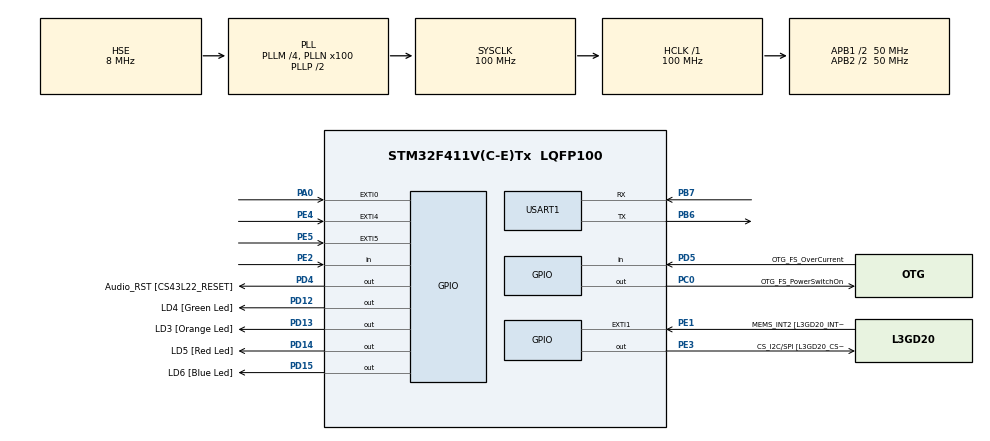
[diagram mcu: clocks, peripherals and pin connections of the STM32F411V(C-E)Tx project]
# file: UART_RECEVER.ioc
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Mcu.Family=STM32F4
Mcu.Name=STM32F411V(C-E)Tx
Mcu.Package=LQFP100
NVIC.PriorityGroup=NVIC_PRIORITYGROUP_0
NVIC.TIM1_UP_TIM10_IRQn=true\:0\:0\:false\:false\:true\:true
NVIC.USART1_IRQn=true\:0\:0\:false\:false\:true\:true
PA0-WKUP.GPIO_ModeDefaultEXTI=GPIO_MODE_EVT_RISING
PA0-WKUP.Signal=GPXTI0
PB6.Mode=Asynchronous
PB6.Signal=USART1_TX
PB7.Mode=Asynchronous
PB7.Signal=USART1_RX
PC0.GPIO_Label=OTG_FS_PowerSwitchOn
PC0.PinState=GPIO_PIN_SET
PC0.Signal=GPIO_Output
PD12.GPIO_Label=LD4 [Green Led]
PD12.GPIO_PuPd=GPIO_NOPULL
PD12.GPIO_Speed=GPIO_SPEED_FREQ_LOW
PD12.Signal=GPIO_Output
PD13.GPIO_Label=LD3 [Orange Led]
PD13.GPIO_PuPd=GPIO_NOPULL
PD13.GPIO_Speed=GPIO_SPEED_FREQ_LOW
PD13.Signal=GPIO_Output
PD14.GPIO_Label=LD5 [Red Led]
PD14.GPIO_PuPd=GPIO_NOPULL
PD14.GPIO_Speed=GPIO_SPEED_FREQ_LOW
PD14.Signal=GPIO_Output
PD15.GPIO_Label=LD6 [Blue Led]
PD15.GPIO_PuPd=GPIO_NOPULL
PD15.GPIO_Speed=GPIO_SPEED_FREQ_LOW
PD15.Signal=GPIO_Output
PD4.GPIO_Label=Audio_RST [CS43L22_RESET]
PD4.Signal=GPIO_Output
PD5.GPIO_Label=OTG_FS_OverCurrent
PD5.Signal=GPIO_Input
PE1.GPIO_Label=MEMS_INT2 [L3GD20_INT2]
PE1.GPIO_ModeDefaultEXTI=GPIO_MODE_EVT_RISING
PE1.Signal=GPXTI1
PE2.Signal=GPIO_Input
PE3.GPIO_Label=CS_I2C/SPI [L3GD20_CS_I2C/SPI]
PE3.Signal=GPIO_Output
PE4.GPIO_ModeDefaultEXTI=GPIO_MODE_EVT_RISING
PE4.Signal=GPXTI4
PE5.GPIO_ModeDefaultEXTI=GPIO_MODE_EVT_RISING
PE5.Signal=GPXTI5
PH0\ -\ OSC_IN.Mode=HSE-External-Oscillator
PH0\ -\ OSC_IN.Signal=RCC_OSC_IN
PH1\ -\ OSC_OUT.Mode=HSE-External-Oscillator
PH1\ -\ OSC_OUT.Signal=RCC_OSC_OUT
ProjectManager.HeapSize=0x200
ProjectManager.StackSize=0x400
ProjectManager.TargetToolchain=SW4STM32
RCC.48MHZClocksFreq_Value=25000000
RCC.AHBFreq_Value=100000000
RCC.APB1CLKDivider=RCC_HCLK_DIV2
RCC.APB1Freq_Value=50000000
RCC.APB1TimFreq_Value=100000000
RCC.APB2CLKDivider=RCC_HCLK_DIV2
RCC.APB2Freq_Value=50000000
RCC.APB2TimFreq_Value=100000000
RCC.CortexFreq_Value=100000000
RCC.HCLKFreq_Value=100000000
RCC.HSE_VALUE=8000000
RCC.HSI_VALUE=16000000
RCC.LSE_VALUE=32768
RCC.PLLI2SM=5
RCC.PLLI2SN=200
RCC.PLLM=4
RCC.PLLN=100
RCC.PLLQ=8
RCC.PLLSourceVirtual=RCC_PLLSOURCE_HSE
RCC.SYSCLKFreq_VALUE=100000000
RCC.SYSCLKSource=RCC_SYSCLKSOURCE_PLLCLK
RCC.VCOOutputFreq_Value=200000000
TIM10.Period=9999
TIM10.Prescaler=9999
USART1.VirtualMode=VM_ASYNC
VP_TIM10_VS_ClockSourceINT.Mode=Enable_Timer
board=32F411EDISCOVERY

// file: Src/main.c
/**
  ******************************************************************************
  * @file           : main.c
  * @brief          : Main program body
  ******************************************************************************
  ** This notice applies to any and all portions of this file
  * that are not between comment pairs USER CODE BEGIN and
  * USER CODE END. Other portions of this file, whether
  * inserted by the user or by software development tools
  * are owned by their respective copyright owners.
  *
  * COPYRIGHT(c) 2018 STMicroelectronics
  *
  * Redistribution and use in source and binary forms, with or without modification,
  * are permitted provided that the following conditions are met:
  *   1. Redistributions of source code must retain the above copyright notice,
  *      this list of conditions and the following disclaimer.
  *   2. Redistributions in binary form must reproduce the above copyright notice,
  *      this list of conditions and the following disclaimer in the documentation
  *      and/or other materials provided with the distribution.
  *   3. Neither the name of STMicroelectronics nor the names of its contributors
  *      may be used to endorse or promote products derived from this software
  *      without specific prior written permission.
  *
  * THIS SOFTWARE IS PROVIDED BY THE COPYRIGHT HOLDERS AND CONTRIBUTORS "AS IS"
  * AND ANY EXPRESS OR IMPLIED WARRANTIES, INCLUDING, BUT NOT LIMITED TO, THE
  * IMPLIED WARRANTIES OF MERCHANTABILITY AND FITNESS FOR A PARTICULAR PURPOSE ARE
  * DISCLAIMED. IN NO EVENT SHALL THE COPYRIGHT HOLDER OR CONTRIBUTORS BE LIABLE
  * FOR ANY DIRECT, INDIRECT, INCIDENTAL, SPECIAL, EXEMPLARY, OR CONSEQUENTIAL
  * DAMAGES (INCLUDING, BUT NOT LIMITED TO, PROCUREMENT OF SUBSTITUTE GOODS OR
  * SERVICES; LOSS OF USE, DATA, OR PROFITS; OR BUSINESS INTERRUPTION) HOWEVER
  * CAUSED AND ON ANY THEORY OF LIABILITY, WHETHER IN CONTRACT, STRICT LIABILITY,
  * OR TORT (INCLUDING NEGLIGENCE OR OTHERWISE) ARISING IN ANY WAY OUT OF THE USE
  * OF THIS SOFTWARE, EVEN IF ADVISED OF THE POSSIBILITY OF SUCH DAMAGE.
  *
  ******************************************************************************
  */
#include "main.h"
#include "stm32f4xx_hal.h"

TIM_HandleTypeDef htim10;

UART_HandleTypeDef huart1;

/* USER CODE BEGIN PV */
/* Private variables ---------------------------------------------------------*/
uint8_t received[10];
/* USER CODE END PV */

void SystemClock_Config(void);
static void MX_GPIO_Init(void);
static void MX_TIM10_Init(void);
static void MX_USART1_UART_Init(void);

/* USER CODE BEGIN PFP */
/* Private function prototypes -----------------------------------------------*/
void HAL_UART_RxCpltCallback(UART_HandleTypeDef *huart) {
	uint8_t data[50];
	uint16_t size = 0;

	size = sprintf(data, "Received msg: %s \n\r", received);

	HAL_UART_Transmit_IT(&huart1, data, size);
	HAL_UART_Receive_IT(&huart1, &received, 10);
	HAL_GPIO_TogglePin(GPIOD, (uint16_t)0xf000);
}
/* USER CODE END PFP */

int main(void)
{

  /* MCU Configuration----------------------------------------------------------*/

  /* Reset of all peripherals, Initializes the Flash interface and the Systick. */
  HAL_Init();

  /* Configure the system clock */
  SystemClock_Config();

  /* Initialize all configured peripherals */
  MX_GPIO_Init();
  MX_TIM10_Init();
  MX_USART1_UART_Init();
  /* USER CODE BEGIN 2 */
  HAL_UART_Receive_IT(&huart1,&received, 10);
  /* USER CODE END 2 */

  /* Infinite loop */
  while (1)
  {

  }

}

void SystemClock_Config(void)
{

  RCC_OscInitTypeDef RCC_OscInitStruct;
  RCC_ClkInitTypeDef RCC_ClkInitStruct;

    /**Configure the main internal regulator output voltage
    */
  __HAL_RCC_PWR_CLK_ENABLE();

  __HAL_PWR_VOLTAGESCALING_CONFIG(PWR_REGULATOR_VOLTAGE_SCALE1);

    /**Initializes the CPU, AHB and APB busses clocks
    */
  RCC_OscInitStruct.OscillatorType = RCC_OSCILLATORTYPE_HSE;
  RCC_OscInitStruct.HSEState = RCC_HSE_ON;
  RCC_OscInitStruct.PLL.PLLState = RCC_PLL_ON;
  RCC_OscInitStruct.PLL.PLLSource = RCC_PLLSOURCE_HSE;
  RCC_OscInitStruct.PLL.PLLM = 4;
  RCC_OscInitStruct.PLL.PLLN = 100;
  RCC_OscInitStruct.PLL.PLLP = RCC_PLLP_DIV2;
  RCC_OscInitStruct.PLL.PLLQ = 8;
  if (HAL_RCC_OscConfig(&RCC_OscInitStruct) != HAL_OK)
  {
    _Error_Handler(__FILE__, __LINE__);
  }

    /**Initializes the CPU, AHB and APB busses clocks
    */
  RCC_ClkInitStruct.ClockType = RCC_CLOCKTYPE_HCLK|RCC_CLOCKTYPE_SYSCLK
                              |RCC_CLOCKTYPE_PCLK1|RCC_CLOCKTYPE_PCLK2;
  RCC_ClkInitStruct.SYSCLKSource = RCC_SYSCLKSOURCE_PLLCLK;
  RCC_ClkInitStruct.AHBCLKDivider = RCC_SYSCLK_DIV1;
  RCC_ClkInitStruct.APB1CLKDivider = RCC_HCLK_DIV2;
  RCC_ClkInitStruct.APB2CLKDivider = RCC_HCLK_DIV2;

  if (HAL_RCC_ClockConfig(&RCC_ClkInitStruct, FLASH_LATENCY_3) != HAL_OK)
  {
    _Error_Handler(__FILE__, __LINE__);
  }

    /**Configure the Systick interrupt time
    */
  HAL_SYSTICK_Config(HAL_RCC_GetHCLKFreq()/1000);

    /**Configure the Systick
    */
  HAL_SYSTICK_CLKSourceConfig(SYSTICK_CLKSOURCE_HCLK);

  /* SysTick_IRQn interrupt configuration */
  HAL_NVIC_SetPriority(SysTick_IRQn, 0, 0);
}

/* TIM10 init function */
static void MX_TIM10_Init(void)
{

  htim10.Instance = TIM10;
  htim10.Init.Prescaler = 9999;
  htim10.Init.CounterMode = TIM_COUNTERMODE_UP;
  htim10.Init.Period = 9999;
  htim10.Init.ClockDivision = TIM_CLOCKDIVISION_DIV1;
  if (HAL_TIM_Base_Init(&htim10) != HAL_OK)
  {
    _Error_Handler(__FILE__, __LINE__);
  }

}

/* USART1 init function */
static void MX_USART1_UART_Init(void)
{

  huart1.Instance = USART1;
  huart1.Init.BaudRate = 115200;
  huart1.Init.WordLength = UART_WORDLENGTH_8B;
  huart1.Init.StopBits = UART_STOPBITS_1;
  huart1.Init.Parity = UART_PARITY_NONE;
  huart1.Init.Mode = UART_MODE_TX_RX;
  huart1.Init.HwFlowCtl = UART_HWCONTROL_NONE;
  huart1.Init.OverSampling = UART_OVERSAMPLING_16;
  if (HAL_UART_Init(&huart1) != HAL_OK)
  {
    _Error_Handler(__FILE__, __LINE__);
  }

}

/** Configure pins as
        * Analog
        * Input
        * Output
        * EVENT_OUT
        * EXTI
*/
static void MX_GPIO_Init(void)
{

  GPIO_InitTypeDef GPIO_InitStruct;

  /* GPIO Ports Clock Enable */
  __HAL_RCC_GPIOE_CLK_ENABLE();
  __HAL_RCC_GPIOH_CLK_ENABLE();
  __HAL_RCC_GPIOC_CLK_ENABLE();
  __HAL_RCC_GPIOA_CLK_ENABLE();
  __HAL_RCC_GPIOD_CLK_ENABLE();
  __HAL_RCC_GPIOB_CLK_ENABLE();

  /*Configure GPIO pin Output Level */
  HAL_GPIO_WritePin(CS_I2C_SPI_GPIO_Port, CS_I2C_SPI_Pin, GPIO_PIN_RESET);

  /*Configure GPIO pin Output Level */
  HAL_GPIO_WritePin(OTG_FS_PowerSwitchOn_GPIO_Port, OTG_FS_PowerSwitchOn_Pin, GPIO_PIN_SET);

  /*Configure GPIO pin Output Level */
  HAL_GPIO_WritePin(GPIOD, LD4_Pin|LD3_Pin|LD5_Pin|LD6_Pin
                          |Audio_RST_Pin, GPIO_PIN_RESET);

  /*Configure GPIO pin : PE2 */
  GPIO_InitStruct.Pin = GPIO_PIN_2;
  GPIO_InitStruct.Mode = GPIO_MODE_INPUT;
  GPIO_InitStruct.Pull = GPIO_NOPULL;
  HAL_GPIO_Init(GPIOE, &GPIO_InitStruct);

  /*Configure GPIO pin : CS_I2C_SPI_Pin */
  GPIO_InitStruct.Pin = CS_I2C_SPI_Pin;
  GPIO_InitStruct.Mode = GPIO_MODE_OUTPUT_PP;
  GPIO_InitStruct.Pull = GPIO_NOPULL;
  GPIO_InitStruct.Speed = GPIO_SPEED_FREQ_LOW;
  HAL_GPIO_Init(CS_I2C_SPI_GPIO_Port, &GPIO_InitStruct);

  /*Configure GPIO pins : PE4 PE5 MEMS_INT2_Pin */
  GPIO_InitStruct.Pin = GPIO_PIN_4|GPIO_PIN_5|MEMS_INT2_Pin;
  GPIO_InitStruct.Mode = GPIO_MODE_EVT_RISING;
  GPIO_InitStruct.Pull = GPIO_NOPULL;
  HAL_GPIO_Init(GPIOE, &GPIO_InitStruct);

  /*Configure GPIO pin : OTG_FS_PowerSwitchOn_Pin */
  GPIO_InitStruct.Pin = OTG_FS_PowerSwitchOn_Pin;
  GPIO_InitStruct.Mode = GPIO_MODE_OUTPUT_PP;
  GPIO_InitStruct.Pull = GPIO_NOPULL;
  GPIO_InitStruct.Speed = GPIO_SPEED_FREQ_LOW;
  HAL_GPIO_Init(OTG_FS_PowerSwitchOn_GPIO_Port, &GPIO_InitStruct);

  /*Configure GPIO pin : PA0 */
  GPIO_InitStruct.Pin = GPIO_PIN_0;
  GPIO_InitStruct.Mode = GPIO_MODE_EVT_RISING;
  GPIO_InitStruct.Pull = GPIO_NOPULL;
  HAL_GPIO_Init(GPIOA, &GPIO_InitStruct);

  /*Configure GPIO pins : LD4_Pin LD3_Pin LD5_Pin LD6_Pin
                           Audio_RST_Pin */
  GPIO_InitStruct.Pin = LD4_Pin|LD3_Pin|LD5_Pin|LD6_Pin
                          |Audio_RST_Pin;
  GPIO_InitStruct.Mode = GPIO_MODE_OUTPUT_PP;
  GPIO_InitStruct.Pull = GPIO_NOPULL;
  GPIO_InitStruct.Speed = GPIO_SPEED_FREQ_LOW;
  HAL_GPIO_Init(GPIOD, &GPIO_InitStruct);

  /*Configure GPIO pin : OTG_FS_OverCurrent_Pin */
  GPIO_InitStruct.Pin = OTG_FS_OverCurrent_Pin;
  GPIO_InitStruct.Mode = GPIO_MODE_INPUT;
  GPIO_InitStruct.Pull = GPIO_NOPULL;
  HAL_GPIO_Init(OTG_FS_OverCurrent_GPIO_Port, &GPIO_InitStruct);

}

void _Error_Handler(char *file, int line)
{
  while(1)
  {
  }
}

/************************ (C) COPYRIGHT STMicroelectronics *****END OF FILE****/
